# STM32H5E4 register map
File version: 1.0
CPU: CM33 r0p0, little endian, MPU, FPU, 4 interrupt priority bits
Registers are 32-bit, read-write, reset 0x0 unless marked. A register's access mark holds for its fields unless they carry their own. Offsets are from the block's base; [hi:lo] are bit positions; {n}, {i} and the like mark numbered series.

## HASH — HASH register bank
Base 0x420C0400
Same registers: HASH_S 0x520C0400
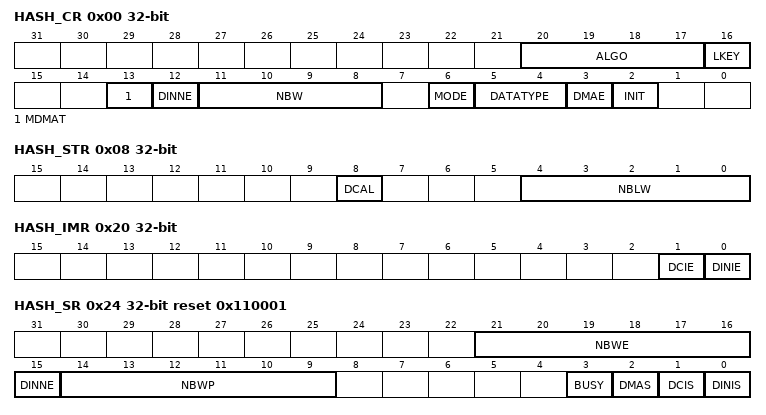
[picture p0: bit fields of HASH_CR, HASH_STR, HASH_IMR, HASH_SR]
0x00 HASH_CR — HASH control register
  [20:17] ALGO — Algorithm selection
    0=SHA-1; 2=SHA2-224; 3=SHA2-256; 12=SHA2-384; 13=SHA2-512/224; 14=SHA2-512/256; 15=SHA2-512; 4=SHA3-224; 5=SHA3-256; 6=SHA3-384; 7=SHA3-512; 8=SHAKE128; 9=SHAKE256
  [16] LKEY — Long key selection
    0=HMAC key is shorter or equal to the block size (short key); 1=HMAC key is longer than the block size (long key)
  [13] MDMAT — Multiple DMA transfers
    0=DCAL is automatically set at the end of a DMA transfer; 1=DCAL is not automatically set at the end of a DMA transfer
  [12] DINNE ro — DIN not empty
  [11:8] NBW ro — Number of words already pushed
  [6] MODE — Mode selection
    0=Hash mode selected; 1=HMAC mode selected
  [5:4] DATATYPE — Data type selection
    0=32-bit data; 1=16-bit data or half-word; 2=8-bit data or bytes; 3=bit data or bit string
  [3] DMAE — DMA enable
    0=DMA transfers disabled; 1=DMA transfers enabled
  [2] INIT — Initialize message digest calculation
0x04 HASH_DIN wo — HASH data input register
  [31:0] DATAIN — Data input
0x08 HASH_STR — HASH start register
  [8] DCAL — Digest calculation
  [4:0] NBLW — Number of valid bits in the last word
    0=All the 32 bits of the last data written are valid message bits, that is M[31:0]; 1=Only one bit of the last data written (after swapping) is valid, that is M[0]; 2=Only two bits of the last data written (after swapping) are valid, that is M[1:0]; 3=Only three bits of the last data written (after swapping) are valid that is M[2:0]; 31=Only 31 bits of the last data written (after swapping) are valid that is M[30:0]
{0xC+4i} HASH_HRA{i} ro (i=0..4) — HASH aliased digest register {i}
  [31:0] H{i} — Hash data x
0x20 HASH_IMR — HASH interrupt enable register
  [1] DCIE — Digest calculation completion interrupt enable
    0=Digest calculation completion interrupt disabled; 1=Digest calculation completion interrupt enabled
  [0] DINIE — Data input interrupt enable
    0=Data input interrupt disabled; 1=Data input interrupt enabled
0x24 HASH_SR reset 0x110001 — HASH status register
  [21:16] NBWE ro — Number of words expected
  [15] DINNE ro — DIN not empty
    0=No data are present in the data input buffer; 1=The input buffer contains at least one word of data
  [14:9] NBWP ro — Number of words already pushed
  [3] BUSY ro — Busy bit
    0=No block is currently being processed; 1=The hash core is processing a block of data
  [2] DMAS ro — DMA Status
    0=DMA interface is disabled (DMAE=0) and no transfer is ongoing; 1=DMA interface is enabled (DMAE=1) or a transfer is ongoing
  [1] DCIS — Digest calculation completion interrupt status
    0=No digest available in the HASH_HRx registers (zeros are returned); 1=Digest calculation complete, a digest is available in the HASH_HRx registers
  [0] DINIS — Data input interrupt status
    0=Less than 16 locations are free in the input buffer; 1=A new block can be entered into the input buffer
{0xF8+4i} HASH_CSR{i} (i=0..102) — HASH context swap register {i}
  [31:0] CS{i} — Context swap x
{0x310+4i} HASH_HR{i} ro (i=0..4) — HASH digest register {i}
  [31:0] H{i} — Hash data x
{0x310+4i} HASH_HR{i} ro (i=5..41) — HASH supplementary digest register {i}
  [31:0] H{i} — Hash data x

## ICACHE — ICACHE register block
Base 0x40030400
Same registers: ICACHE_S 0x50030400
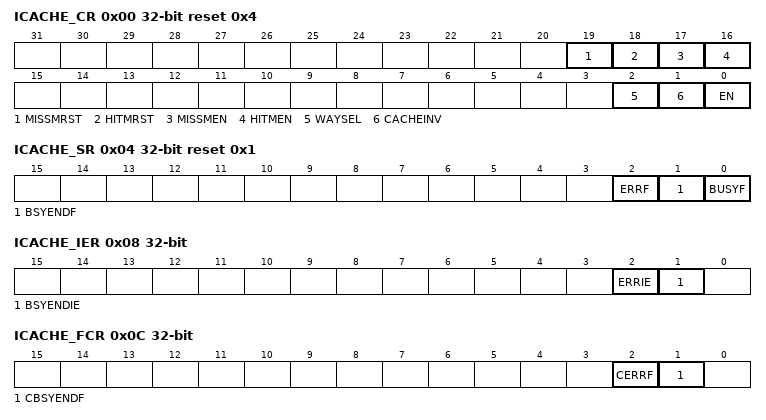
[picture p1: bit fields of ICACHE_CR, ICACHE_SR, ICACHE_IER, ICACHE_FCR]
0x00 ICACHE_CR reset 0x4 — ICACHE control register
  [19] MISSMRST — miss monitor reset
    0=release the cache miss monitor reset (needed to enable the counting); 1=reset cache miss monitor
  [18] HITMRST — hit monitor reset
    0=release the cache miss monitor reset (needed to enable the counting); 1=reset cache hit monitor
  [17] MISSMEN — miss monitor enable
    0=cache miss monitor switched off; 1=cache miss monitor enabled
  [16] HITMEN — hit monitor enable
    0=cache hit monitor switched off; 1=cache hit monitor enabled
  [2] WAYSEL — cache associativity mode selection
    0=direct mapped cache (1-way cache); 1=n-way set associative cache (reset value)
  [1] CACHEINV wo — cache invalidation
    0=no effect; 1=invalidate entire cache (all cache lines valid bit = 0)
  [0] EN — enable
    0=cache disabled; 1=cache enabled
0x04 ICACHE_SR ro reset 0x1 — ICACHE status register
  [2] ERRF — cache error flag
    0=no error; 1=an error occurred during the operation (cacheable write)
  [1] BSYENDF — busy end flag
    0=cache busy; 1=full invalidate CACHEINV operation finished
  [0] BUSYF — busy flag
    0=cache not busy on a CACHEINV operation; 1=cache executing a full invalidate CACHEINV operation
0x08 ICACHE_IER — ICACHE interrupt enable register
  [2] ERRIE — interrupt enable on cache error
    0=interrupt disabled on error; 1=interrupt enabled on error
  [1] BSYENDIE — interrupt enable on busy end
    0=interrupt disabled on busy end; 1=interrupt enabled on busy end
0x0C ICACHE_FCR wo — ICACHE flag clear register
  [2] CERRF — clear cache error flag
    0=no effect; 1=clears ERRF flag in ICACHE_SR
  [1] CBSYENDF — clear busy end flag
    0=no effect; 1=clears BSYENDF flag in ICACHE_SR
0x10 ICACHE_HMONR ro — ICACHE hit monitor register
  [31:0] HITMON — cache hit monitor counter
0x14 ICACHE_MMONR ro — ICACHE miss monitor register
  [15:0] MISSMON — cache miss monitor counter
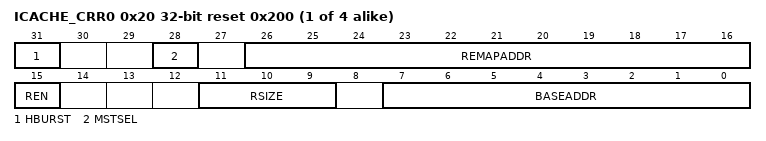
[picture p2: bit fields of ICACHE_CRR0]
{0x20+4i} ICACHE_CRR{i} reset 0x200 (i=0..3) — ICACHE region {i} configuration register
  [31] HBURST — output burst type for region x
    0=WRAP; 1=INCR
  [28] MSTSEL — AHB cache master selection for region x
    0=no action (master1 selected by default); 1=master2 selected
  [26:16] REMAPADDR — remapped address for region x
  [15] REN — enable for region x
    0=disabled; 1=enabled
  [11:9] RSIZE — size for region x
    1=2 Mbytes; 2=4 Mbytes; 3=8 Mbytes; 4=16 Mbytes; 5=32 Mbytes; 6=64 Mbytes; 7=128 Mbytes
  [7:0] BASEADDR — base address for region x
